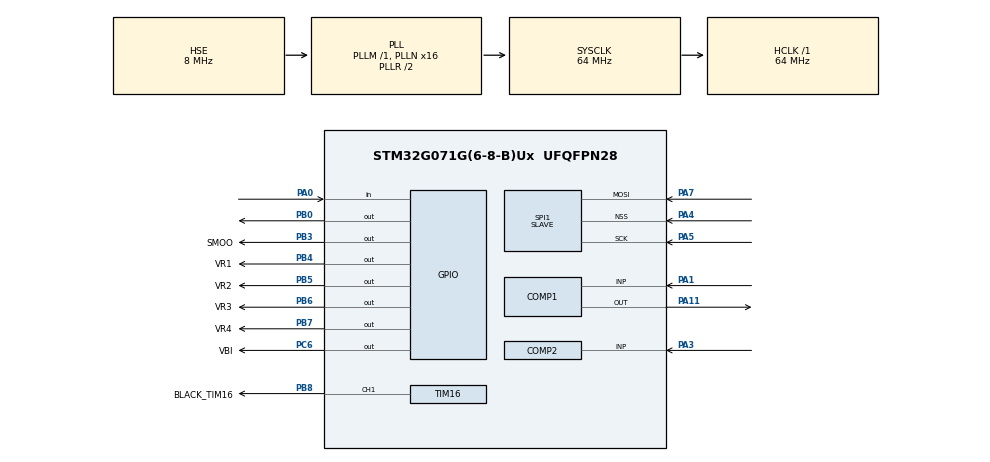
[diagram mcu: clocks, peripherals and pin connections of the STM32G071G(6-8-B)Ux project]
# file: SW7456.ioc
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COMP1.Hysteresis=COMP_HYSTERESIS_LOW
COMP1.Mode=COMP_POWERMODE_MEDIUMSPEED
COMP1.TriggerMode=COMP_TRIGGERMODE_IT_RISING
COMP1.WindowOutput=COMP_WINDOWOUTPUT_EACH_COMP
COMP2.Hysteresis=COMP_HYSTERESIS_LOW
COMP2.Mode=COMP_POWERMODE_MEDIUMSPEED
COMP2.OutputPol=COMP_OUTPUTPOL_NONINVERTED
COMP2.TriggerMode=COMP_TRIGGERMODE_IT_RISING
DAC1.DAC_Channel-DAC_OUT2_Int=DAC_CHANNEL_2
Dma.Request0=SPI1_RX
Dma.Request1=TIM16_CH1
Dma.SPI1_RX.0.Direction=DMA_PERIPH_TO_MEMORY
Dma.SPI1_RX.0.EventEnable=DISABLE
Dma.SPI1_RX.0.Instance=DMA1_Channel2
Dma.SPI1_RX.0.MemDataAlignment=DMA_MDATAALIGN_BYTE
Dma.SPI1_RX.0.MemInc=DMA_MINC_ENABLE
Dma.SPI1_RX.0.Mode=DMA_CIRCULAR
Dma.SPI1_RX.0.PeriphDataAlignment=DMA_PDATAALIGN_BYTE
Dma.SPI1_RX.0.PeriphInc=DMA_PINC_DISABLE
Dma.SPI1_RX.0.Polarity=HAL_DMAMUX_REQ_GEN_RISING
Dma.SPI1_RX.0.Priority=DMA_PRIORITY_LOW
Dma.SPI1_RX.0.RequestNumber=1
Dma.SPI1_RX.0.SignalID=NONE
Dma.SPI1_RX.0.SyncEnable=DISABLE
Dma.SPI1_RX.0.SyncPolarity=HAL_DMAMUX_SYNC_NO_EVENT
Dma.SPI1_RX.0.SyncRequestNumber=1
Dma.SPI1_RX.0.SyncSignalID=NONE
Dma.TIM16_CH1.1.Direction=DMA_MEMORY_TO_PERIPH
Dma.TIM16_CH1.1.EventEnable=DISABLE
Dma.TIM16_CH1.1.Instance=DMA1_Channel5
Dma.TIM16_CH1.1.MemDataAlignment=DMA_MDATAALIGN_HALFWORD
Dma.TIM16_CH1.1.MemInc=DMA_MINC_ENABLE
Dma.TIM16_CH1.1.Mode=DMA_CIRCULAR
Dma.TIM16_CH1.1.PeriphDataAlignment=DMA_PDATAALIGN_HALFWORD
Dma.TIM16_CH1.1.PeriphInc=DMA_PINC_DISABLE
Dma.TIM16_CH1.1.Polarity=HAL_DMAMUX_REQ_GEN_RISING
Dma.TIM16_CH1.1.Priority=DMA_PRIORITY_VERY_HIGH
Dma.TIM16_CH1.1.RequestNumber=1
Dma.TIM16_CH1.1.SignalID=NONE
Dma.TIM16_CH1.1.SyncEnable=DISABLE
Dma.TIM16_CH1.1.SyncPolarity=HAL_DMAMUX_SYNC_NO_EVENT
Dma.TIM16_CH1.1.SyncRequestNumber=1
Dma.TIM16_CH1.1.SyncSignalID=NONE
LPTIM1.TriggerSource=LPTIM_TRIGSOURCE_6
Mcu.Family=STM32G0
Mcu.Name=STM32G071G(6-8-B)Ux
Mcu.Package=UFQFPN28
NVIC.ADC1_COMP_IRQn=true\:0\:0\:true\:false\:true\:false\:true\:true
NVIC.DMA1_Ch4_7_DMAMUX1_OVR_IRQn=true\:0\:0\:false\:false\:true\:false\:true\:true
NVIC.DMA1_Channel2_3_IRQn=true\:3\:0\:true\:false\:true\:false\:true\:true
PA0.GPIO_PuPd=GPIO_PULLDOWN
PA0.Signal=GPIO_Input
PA1.Mode=INP
PA1.Signal=COMP1_INP
PA11\ [PA9].Mode=ExternalOutput
PA11\ [PA9].Signal=COMP1_OUT
PA12\ [PA10].GPIO_Speed=GPIO_SPEED_FREQ_MEDIUM
PA12\ [PA10].PinState=GPIO_PIN_SET
PA12\ [PA10].Signal=COMP2_OUT
PA13.Mode=Serial_Wire
PA13.Signal=SYS_SWDIO
PA14-BOOT0.Mode=Serial_Wire
PA14-BOOT0.Signal=SYS_SWCLK
PA3.Mode=INP
PA3.Signal=COMP2_INP
PA4.GPIO_PuPd=GPIO_PULLUP
PA4.GPIO_Speed=GPIO_SPEED_FREQ_HIGH
PA4.Mode=NSS_Signal_Hard_Input
PA4.Signal=SPI1_NSS
PA5.GPIO_PuPd=GPIO_PULLUP
PA5.GPIO_Speed=GPIO_SPEED_FREQ_HIGH
PA5.Mode=RX_Only_Simplex_Unidirect_Slave
PA5.Signal=SPI1_SCK
PA6.Signal=SPI1_MISO
PA7.GPIO_PuPd=GPIO_PULLUP
PA7.GPIO_Speed=GPIO_SPEED_FREQ_HIGH
PA7.Mode=RX_Only_Simplex_Unidirect_Slave
PA7.Signal=SPI1_MOSI
PB0.GPIO_ModeDefaultOutputPP=GPIO_MODE_OUTPUT_PP
PB0.GPIO_Speed=GPIO_SPEED_FREQ_VERY_HIGH
PB0.Signal=GPIO_Output
PB3.GPIO_Label=SMOO
PB3.GPIO_ModeDefaultOutputPP=GPIO_MODE_OUTPUT_OD
PB3.GPIO_Speed=GPIO_SPEED_FREQ_HIGH
PB3.PinState=GPIO_PIN_SET
PB3.Signal=GPIO_Output
PB4.GPIO_Label=VR1
PB4.GPIO_Speed=GPIO_SPEED_FREQ_MEDIUM
PB4.Signal=GPIO_Output
PB5.GPIO_Label=VR2
PB5.GPIO_Speed=GPIO_SPEED_FREQ_MEDIUM
PB5.Signal=GPIO_Output
PB6.GPIO_Label=VR3
PB6.GPIO_PuPd=GPIO_NOPULL
PB6.GPIO_Speed=GPIO_SPEED_FREQ_MEDIUM
PB6.Signal=GPIO_Output
PB7.GPIO_Label=VR4
PB7.GPIO_Speed=GPIO_SPEED_FREQ_MEDIUM
PB7.Signal=GPIO_Output
PB8.GPIO_Label=BLACK_TIM16
PB8.Signal=S_TIM16_CH1
PC14-OSC32_IN\ (PC14).Mode=HSE-External-Clock-Source
PC14-OSC32_IN\ (PC14).Signal=RCC_OSC_IN
PC6.GPIO_Label=VBI
PC6.Signal=GPIO_Output
ProjectManager.HeapSize=0x0
ProjectManager.StackSize=0x100
ProjectManager.TargetToolchain=STM32CubeIDE
RCC.ADCFreq_Value=64000000
RCC.AHBFreq_Value=64000000
RCC.CortexFreq_Value=64000000
RCC.EXTERNAL_CLOCK_VALUE=48000
RCC.HCLKFreq_Value=64000000
RCC.HSE_VALUE=8000000
RCC.HSI_VALUE=16000000
RCC.LSE_VALUE=32768
RCC.PLLN=16
RCC.PLLQ=RCC_PLLQ_DIV8
RCC.PLLSourceVirtual=RCC_PLLSOURCE_HSE
RCC.SYSCLKFreq_VALUE=64000000
RCC.SYSCLKSource=RCC_SYSCLKSOURCE_PLLCLK
RCC.VCOOutputFreq_Value=128000000
SH.S_TIM16_CH1.0=TIM16_CH1,PWM Generation1 CH1
SPI1.CLKPhase=SPI_PHASE_2EDGE
SPI1.CLKPolarity=SPI_POLARITY_HIGH
SPI1.DataSize=SPI_DATASIZE_8BIT
SPI1.Direction=SPI_DIRECTION_2LINES_RXONLY
SPI1.FirstBit=SPI_FIRSTBIT_MSB
SPI1.Mode=SPI_MODE_SLAVE
SPI1.VirtualNSS=VM_NSSHARD
SPI1.VirtualType=VM_SLAVE
TIM1.AutoReloadPreload=TIM_AUTORELOAD_PRELOAD_ENABLE
TIM1.Period=40000
TIM1.Prescaler=31
TIM1.RepetitionCounter=0
TIM14.AutoReloadPreload=TIM_AUTORELOAD_PRELOAD_ENABLE
TIM14.Channel=TIM_CHANNEL_1
TIM14.ClockDivision=TIM_CLOCKDIVISION_DIV1
TIM14.ICFilter_CH1=2
TIM14.ICPrescaler=TIM_ICPSC_DIV1
TIM14.Period=65535
TIM14.TIM14_TI1_REMAP=TIM_TIM14_TI1_HSE_32
TIM16.Channel=TIM_CHANNEL_1
TIM16.OC1Preload_PWM=ENABLE
TIM16.OCFastMode_PWM=TIM_OCFAST_DISABLE
TIM16.OCIdleState_1=TIM_OCIDLESTATE_RESET
TIM16.OCMode_PWM=TIM_OCMODE_PWM2
TIM16.Period=2034
TIM16.Pulse=0
TIM2.AutoReloadPreload=TIM_AUTORELOAD_PRELOAD_ENABLE
TIM2.Channel-Input_Capture2_from_TI2_Remap_TIM2=TIM_CHANNEL_2
TIM2.ICFilter_CH2=0
TIM2.ICPolarity_CH2=TIM_INPUTCHANNELPOLARITY_RISING
TIM2.ICPrescaler-Input_Capture2_from_TI2_Remap_TIM2=TIM_ICPSC_DIV1
TIM2.Period=32000
TIM2.Slave_TriggerPrescaler=TIM_TRIGGERPRESCALER_DIV1
TIM2.TIM2_ETR_REMAP-TriggerSource_ETR_Remap_TIM2=TIM_TIM2_ETR_COMP2
TIM2.TIM_MasterOutputTrigger=TIM_TRGO_OC1REF
TIM2.TIM_MasterSlaveMode=TIM_MASTERSLAVEMODE_DISABLE
TIM3.AutoReloadPreload=TIM_AUTORELOAD_PRELOAD_ENABLE
TIM3.Channel-Input_Capture1_from_TI1_REMAP_TIM3=TIM_CHANNEL_1
TIM3.Period=65535
TIM3.Slave_TriggerPolarity=TIM_TRIGGERPOLARITY_NONINVERTED
TIM3.Slave_TriggerPrescaler=TIM_TRIGGERPRESCALER_DIV1
TIM3.TIM3_ETR_REMAP-TriggerSource_ETR_Remap_TIM3=TIM_TIM3_ETR_COMP1
TIM3.TIM_MasterOutputTrigger=TIM_TRGO_OC1REF
TIM6.AutoReloadPreload=TIM_AUTORELOAD_PRELOAD_ENABLE
TIM6.Period=0xffff
TIM6.TIM_MasterOutputTrigger=TIM_TRGO_ENABLE
VP_COMP1_VS_DACOUT2.Mode=INM_DACOUT2
VP_COMP2_VS_DACOUT2.Mode=INM_DACOUT2
VP_DAC1_VS_DACI2.Mode=DAC_OUT2_Int
VP_LPTIM1_VS_LPTIM_counterModeInternalClock.Mode=Counts__internal_clock_event_00
VP_SYS_VS_DBSignals.Mode=DisableDeadBatterySignals
VP_TIM14_VS_ClockSourceINT.Mode=Enable_Timer
VP_TIM14_VS_NoInput1.Mode=Input_Capture1_from_TI1_REMAP_TIM14
VP_TIM16_VS_ClockSourceINT.Mode=Enable_Timer
VP_TIM1_VS_ClockSourceINT.Mode=Internal
VP_TIM2_VS_ClockSourceINT.Mode=Internal
VP_TIM2_VS_ControllerModeCombinedResetTrigger.Mode=Combined_Reset_Trigger_Mode
VP_TIM2_VS_NoETR.Mode=TriggerSource_ETR_Remap_TIM2
VP_TIM2_VS_NoInput2.Mode=Input_Capture2_from_TI2_Remap_TIM2
VP_TIM3_VS_ClockSourceINT.Mode=Internal
VP_TIM3_VS_ControllerModeCombinedResetTrigger.Mode=Combined_Reset_Trigger_Mode
VP_TIM3_VS_NoETR.Mode=TriggerSource_ETR_Remap_TIM3
VP_TIM3_VS_NoInput1.Mode=Input_Capture1_from_TI1_REMAP_TIM3
VP_TIM6_VS_ClockSourceINT.Mode=Enable_Timer
board=custom

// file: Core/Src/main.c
/* USER CODE BEGIN Header */
/**
  ******************************************************************************
  * @file           : main.c
  * @brief          : Main program body
  ******************************************************************************
  * @attention
  *
  * Copyright (c) 2024 STMicroelectronics.
  * All rights reserved.
  *
  * This software is licensed under terms that can be found in the LICENSE file
  * in the root directory of this software component.
  * If no LICENSE file comes with this software, it is provided AS-IS.
  *
  ******************************************************************************
  */
/* USER CODE END Header */
#include "main.h"

/* USER CODE BEGIN Includes */
#include "osd_glue.h"
/* USER CODE END Includes */

COMP_HandleTypeDef hcomp1;
COMP_HandleTypeDef hcomp2;

DAC_HandleTypeDef hdac1;

LPTIM_HandleTypeDef hlptim1;

SPI_HandleTypeDef hspi1;
DMA_HandleTypeDef hdma_spi1_rx;

TIM_HandleTypeDef htim1;
TIM_HandleTypeDef htim2;
TIM_HandleTypeDef htim3;
TIM_HandleTypeDef htim6;
TIM_HandleTypeDef htim14;
TIM_HandleTypeDef htim16;
DMA_HandleTypeDef hdma_tim16_ch1;

void SystemClock_Config(void);
static void MX_GPIO_Init(void);
static void MX_DMA_Init(void);
static void MX_COMP1_Init(void);
static void MX_DAC1_Init(void);
static void MX_TIM3_Init(void);
static void MX_TIM6_Init(void);
static void MX_TIM2_Init(void);
static void MX_LPTIM1_Init(void);
static void MX_SPI1_Init(void);
static void MX_COMP2_Init(void);
static void MX_TIM1_Init(void);
static void MX_TIM14_Init(void);
static void MX_TIM16_Init(void);

int main(void)
{

  /* MCU Configuration--------------------------------------------------------*/

  /* Reset of all peripherals, Initializes the Flash interface and the Systick. */
  HAL_Init();

  /* Configure the system clock */
  SystemClock_Config();

  /* Initialize all configured peripherals */
  MX_GPIO_Init();
  MX_DMA_Init();
  MX_COMP1_Init();
  MX_DAC1_Init();
  MX_TIM3_Init();
  MX_TIM6_Init();
  MX_TIM2_Init();
  MX_LPTIM1_Init();
  MX_SPI1_Init();
  MX_COMP2_Init();
  MX_TIM1_Init();
  MX_TIM14_Init();
  MX_TIM16_Init();
  /* USER CODE BEGIN 2 */
  osd_init();
  osd_loop();
  /* USER CODE END 2 */

  /* Infinite loop */
  while (1)
  {

  }
}

void SystemClock_Config(void)
{
  RCC_OscInitTypeDef RCC_OscInitStruct = {0};
  RCC_ClkInitTypeDef RCC_ClkInitStruct = {0};

  /** Configure the main internal regulator output voltage
  */
  HAL_PWREx_ControlVoltageScaling(PWR_REGULATOR_VOLTAGE_SCALE1);

  /** Initializes the RCC Oscillators according to the specified parameters
  * in the RCC_OscInitTypeDef structure.
  */
  RCC_OscInitStruct.OscillatorType = RCC_OSCILLATORTYPE_HSE;
  RCC_OscInitStruct.HSEState = RCC_HSE_BYPASS;
  RCC_OscInitStruct.PLL.PLLState = RCC_PLL_ON;
  RCC_OscInitStruct.PLL.PLLSource = RCC_PLLSOURCE_HSE;
  RCC_OscInitStruct.PLL.PLLM = RCC_PLLM_DIV1;
  RCC_OscInitStruct.PLL.PLLN = 16;
  RCC_OscInitStruct.PLL.PLLP = RCC_PLLP_DIV2;
  RCC_OscInitStruct.PLL.PLLQ = RCC_PLLQ_DIV8;
  RCC_OscInitStruct.PLL.PLLR = RCC_PLLR_DIV2;
  if (HAL_RCC_OscConfig(&RCC_OscInitStruct) != HAL_OK)
  {
    Error_Handler();
  }

  /** Initializes the CPU, AHB and APB buses clocks
  */
  RCC_ClkInitStruct.ClockType = RCC_CLOCKTYPE_HCLK|RCC_CLOCKTYPE_SYSCLK
                              |RCC_CLOCKTYPE_PCLK1;
  RCC_ClkInitStruct.SYSCLKSource = RCC_SYSCLKSOURCE_PLLCLK;
  RCC_ClkInitStruct.AHBCLKDivider = RCC_SYSCLK_DIV1;
  RCC_ClkInitStruct.APB1CLKDivider = RCC_HCLK_DIV1;

  if (HAL_RCC_ClockConfig(&RCC_ClkInitStruct, FLASH_LATENCY_2) != HAL_OK)
  {
    Error_Handler();
  }
}

static void MX_COMP1_Init(void)
{

  hcomp1.Instance = COMP1;
  hcomp1.Init.InputPlus = COMP_INPUT_PLUS_IO3;
  hcomp1.Init.InputMinus = COMP_INPUT_MINUS_DAC1_CH2;
  hcomp1.Init.OutputPol = COMP_OUTPUTPOL_NONINVERTED;
  hcomp1.Init.WindowOutput = COMP_WINDOWOUTPUT_EACH_COMP;
  hcomp1.Init.Hysteresis = COMP_HYSTERESIS_LOW;
  hcomp1.Init.BlankingSrce = COMP_BLANKINGSRC_NONE;
  hcomp1.Init.Mode = COMP_POWERMODE_MEDIUMSPEED;
  hcomp1.Init.WindowMode = COMP_WINDOWMODE_DISABLE;
  hcomp1.Init.TriggerMode = COMP_TRIGGERMODE_IT_RISING;
  if (HAL_COMP_Init(&hcomp1) != HAL_OK)
  {
    Error_Handler();
  }

}

static void MX_COMP2_Init(void)
{

  hcomp2.Instance = COMP2;
  hcomp2.Init.InputPlus = COMP_INPUT_PLUS_IO3;
  hcomp2.Init.InputMinus = COMP_INPUT_MINUS_DAC1_CH2;
  hcomp2.Init.OutputPol = COMP_OUTPUTPOL_NONINVERTED;
  hcomp2.Init.WindowOutput = COMP_WINDOWOUTPUT_EACH_COMP;
  hcomp2.Init.Hysteresis = COMP_HYSTERESIS_LOW;
  hcomp2.Init.BlankingSrce = COMP_BLANKINGSRC_NONE;
  hcomp2.Init.Mode = COMP_POWERMODE_MEDIUMSPEED;
  hcomp2.Init.WindowMode = COMP_WINDOWMODE_DISABLE;
  hcomp2.Init.TriggerMode = COMP_TRIGGERMODE_IT_RISING;
  if (HAL_COMP_Init(&hcomp2) != HAL_OK)
  {
    Error_Handler();
  }

}

static void MX_DAC1_Init(void)
{

  DAC_ChannelConfTypeDef sConfig = {0};

  /** DAC Initialization
  */
  hdac1.Instance = DAC1;
  if (HAL_DAC_Init(&hdac1) != HAL_OK)
  {
    Error_Handler();
  }

  /** DAC channel OUT2 config
  */
  sConfig.DAC_SampleAndHold = DAC_SAMPLEANDHOLD_DISABLE;
  sConfig.DAC_Trigger = DAC_TRIGGER_NONE;
  sConfig.DAC_OutputBuffer = DAC_OUTPUTBUFFER_DISABLE;
  sConfig.DAC_ConnectOnChipPeripheral = DAC_CHIPCONNECT_ENABLE;
  sConfig.DAC_UserTrimming = DAC_TRIMMING_FACTORY;
  if (HAL_DAC_ConfigChannel(&hdac1, &sConfig, DAC_CHANNEL_2) != HAL_OK)
  {
    Error_Handler();
  }

}

static void MX_LPTIM1_Init(void)
{

  hlptim1.Instance = LPTIM1;
  hlptim1.Init.Clock.Source = LPTIM_CLOCKSOURCE_APBCLOCK_LPOSC;
  hlptim1.Init.Clock.Prescaler = LPTIM_PRESCALER_DIV1;
  hlptim1.Init.Trigger.Source = LPTIM_TRIGSOURCE_6;
  hlptim1.Init.Trigger.ActiveEdge = LPTIM_ACTIVEEDGE_RISING;
  hlptim1.Init.Trigger.SampleTime = LPTIM_TRIGSAMPLETIME_DIRECTTRANSITION;
  hlptim1.Init.OutputPolarity = LPTIM_OUTPUTPOLARITY_HIGH;
  hlptim1.Init.UpdateMode = LPTIM_UPDATE_IMMEDIATE;
  hlptim1.Init.CounterSource = LPTIM_COUNTERSOURCE_INTERNAL;
  hlptim1.Init.Input1Source = LPTIM_INPUT1SOURCE_GPIO;
  hlptim1.Init.Input2Source = LPTIM_INPUT2SOURCE_GPIO;
  if (HAL_LPTIM_Init(&hlptim1) != HAL_OK)
  {
    Error_Handler();
  }

}

static void MX_SPI1_Init(void)
{

  /* SPI1 parameter configuration*/
  hspi1.Instance = SPI1;
  hspi1.Init.Mode = SPI_MODE_SLAVE;
  hspi1.Init.Direction = SPI_DIRECTION_2LINES_RXONLY;
  hspi1.Init.DataSize = SPI_DATASIZE_8BIT;
  hspi1.Init.CLKPolarity = SPI_POLARITY_HIGH;
  hspi1.Init.CLKPhase = SPI_PHASE_2EDGE;
  hspi1.Init.NSS = SPI_NSS_HARD_INPUT;
  hspi1.Init.FirstBit = SPI_FIRSTBIT_MSB;
  hspi1.Init.TIMode = SPI_TIMODE_DISABLE;
  hspi1.Init.CRCCalculation = SPI_CRCCALCULATION_DISABLE;
  hspi1.Init.CRCPolynomial = 7;
  hspi1.Init.CRCLength = SPI_CRC_LENGTH_DATASIZE;
  hspi1.Init.NSSPMode = SPI_NSS_PULSE_DISABLE;
  if (HAL_SPI_Init(&hspi1) != HAL_OK)
  {
    Error_Handler();
  }

}

static void MX_TIM1_Init(void)
{

  TIM_ClockConfigTypeDef sClockSourceConfig = {0};
  TIM_MasterConfigTypeDef sMasterConfig = {0};

  htim1.Instance = TIM1;
  htim1.Init.Prescaler = 31;
  htim1.Init.CounterMode = TIM_COUNTERMODE_UP;
  htim1.Init.Period = 40000;
  htim1.Init.ClockDivision = TIM_CLOCKDIVISION_DIV1;
  htim1.Init.RepetitionCounter = 0;
  htim1.Init.AutoReloadPreload = TIM_AUTORELOAD_PRELOAD_ENABLE;
  if (HAL_TIM_Base_Init(&htim1) != HAL_OK)
  {
    Error_Handler();
  }
  sClockSourceConfig.ClockSource = TIM_CLOCKSOURCE_INTERNAL;
  if (HAL_TIM_ConfigClockSource(&htim1, &sClockSourceConfig) != HAL_OK)
  {
    Error_Handler();
  }
  sMasterConfig.MasterOutputTrigger = TIM_TRGO_RESET;
  sMasterConfig.MasterOutputTrigger2 = TIM_TRGO2_RESET;
  sMasterConfig.MasterSlaveMode = TIM_MASTERSLAVEMODE_DISABLE;
  if (HAL_TIMEx_MasterConfigSynchronization(&htim1, &sMasterConfig) != HAL_OK)
  {
    Error_Handler();
  }

}

static void MX_TIM2_Init(void)
{

  TIM_ClockConfigTypeDef sClockSourceConfig = {0};
  TIM_SlaveConfigTypeDef sSlaveConfig = {0};
  TIM_MasterConfigTypeDef sMasterConfig = {0};
  TIM_IC_InitTypeDef sConfigIC = {0};

  htim2.Instance = TIM2;
  htim2.Init.Prescaler = 0;
  htim2.Init.CounterMode = TIM_COUNTERMODE_UP;
  htim2.Init.Period = 32000;
  htim2.Init.ClockDivision = TIM_CLOCKDIVISION_DIV1;
  htim2.Init.AutoReloadPreload = TIM_AUTORELOAD_PRELOAD_ENABLE;
  if (HAL_TIM_Base_Init(&htim2) != HAL_OK)
  {
    Error_Handler();
  }
  sClockSourceConfig.ClockSource = TIM_CLOCKSOURCE_INTERNAL;
  if (HAL_TIM_ConfigClockSource(&htim2, &sClockSourceConfig) != HAL_OK)
  {
    Error_Handler();
  }
  if (HAL_TIM_IC_Init(&htim2) != HAL_OK)
  {
    Error_Handler();
  }
  sSlaveConfig.SlaveMode = TIM_SLAVEMODE_COMBINED_RESETTRIGGER;
  sSlaveConfig.InputTrigger = TIM_TS_ETRF;
  sSlaveConfig.TriggerPolarity = TIM_TRIGGERPOLARITY_NONINVERTED;
  sSlaveConfig.TriggerPrescaler = TIM_TRIGGERPRESCALER_DIV1;
  sSlaveConfig.TriggerFilter = 0;
  if (HAL_TIM_SlaveConfigSynchro(&htim2, &sSlaveConfig) != HAL_OK)
  {
    Error_Handler();
  }
  sMasterConfig.MasterOutputTrigger = TIM_TRGO_OC1REF;
  sMasterConfig.MasterSlaveMode = TIM_MASTERSLAVEMODE_DISABLE;
  if (HAL_TIMEx_MasterConfigSynchronization(&htim2, &sMasterConfig) != HAL_OK)
  {
    Error_Handler();
  }
  if (HAL_TIMEx_RemapConfig(&htim2, TIM_TIM2_ETR_COMP2) != HAL_OK)
  {
    Error_Handler();
  }
  sConfigIC.ICPolarity = TIM_INPUTCHANNELPOLARITY_RISING;
  sConfigIC.ICSelection = TIM_ICSELECTION_DIRECTTI;
  sConfigIC.ICPrescaler = TIM_ICPSC_DIV1;
  sConfigIC.ICFilter = 0;
  if (HAL_TIM_IC_ConfigChannel(&htim2, &sConfigIC, TIM_CHANNEL_2) != HAL_OK)
  {
    Error_Handler();
  }
  if (HAL_TIMEx_TISelection(&htim2, TIM_TIM2_TI2_COMP2, TIM_CHANNEL_2) != HAL_OK)
  {
    Error_Handler();
  }

}

static void MX_TIM3_Init(void)
{

  TIM_ClockConfigTypeDef sClockSourceConfig = {0};
  TIM_SlaveConfigTypeDef sSlaveConfig = {0};
  TIM_MasterConfigTypeDef sMasterConfig = {0};
  TIM_IC_InitTypeDef sConfigIC = {0};

  htim3.Instance = TIM3;
  htim3.Init.Prescaler = 0;
  htim3.Init.CounterMode = TIM_COUNTERMODE_UP;
  htim3.Init.Period = 65535;
  htim3.Init.ClockDivision = TIM_CLOCKDIVISION_DIV1;
  htim3.Init.AutoReloadPreload = TIM_AUTORELOAD_PRELOAD_ENABLE;
  if (HAL_TIM_Base_Init(&htim3) != HAL_OK)
  {
    Error_Handler();
  }
  sClockSourceConfig.ClockSource = TIM_CLOCKSOURCE_INTERNAL;
  if (HAL_TIM_ConfigClockSource(&htim3, &sClockSourceConfig) != HAL_OK)
  {
    Error_Handler();
  }
  if (HAL_TIM_IC_Init(&htim3) != HAL_OK)
  {
    Error_Handler();
  }
  sSlaveConfig.SlaveMode = TIM_SLAVEMODE_COMBINED_RESETTRIGGER;
  sSlaveConfig.InputTrigger = TIM_TS_ETRF;
  sSlaveConfig.TriggerPolarity = TIM_TRIGGERPOLARITY_NONINVERTED;
  sSlaveConfig.TriggerPrescaler = TIM_TRIGGERPRESCALER_DIV1;
  sSlaveConfig.TriggerFilter = 0;
  if (HAL_TIM_SlaveConfigSynchro(&htim3, &sSlaveConfig) != HAL_OK)
  {
    Error_Handler();
  }
  sMasterConfig.MasterOutputTrigger = TIM_TRGO_OC1REF;
  sMasterConfig.MasterSlaveMode = TIM_MASTERSLAVEMODE_DISABLE;
  if (HAL_TIMEx_MasterConfigSynchronization(&htim3, &sMasterConfig) != HAL_OK)
  {
    Error_Handler();
  }
  if (HAL_TIMEx_RemapConfig(&htim3, TIM_TIM3_ETR_COMP1) != HAL_OK)
  {
    Error_Handler();
  }
  sConfigIC.ICPolarity = TIM_INPUTCHANNELPOLARITY_RISING;
  sConfigIC.ICSelection = TIM_ICSELECTION_DIRECTTI;
  sConfigIC.ICPrescaler = TIM_ICPSC_DIV1;
  sConfigIC.ICFilter = 0;
  if (HAL_TIM_IC_ConfigChannel(&htim3, &sConfigIC, TIM_CHANNEL_1) != HAL_OK)
  {
    Error_Handler();
  }
  if (HAL_TIMEx_TISelection(&htim3, TIM_TIM3_TI1_COMP1, TIM_CHANNEL_1) != HAL_OK)
  {
    Error_Handler();
  }

}

static void MX_TIM6_Init(void)
{

  TIM_MasterConfigTypeDef sMasterConfig = {0};

  htim6.Instance = TIM6;
  htim6.Init.Prescaler = 0;
  htim6.Init.CounterMode = TIM_COUNTERMODE_UP;
  htim6.Init.Period = 0xffff;
  htim6.Init.AutoReloadPreload = TIM_AUTORELOAD_PRELOAD_ENABLE;
  if (HAL_TIM_Base_Init(&htim6) != HAL_OK)
  {
    Error_Handler();
  }
  sMasterConfig.MasterOutputTrigger = TIM_TRGO_ENABLE;
  sMasterConfig.MasterSlaveMode = TIM_MASTERSLAVEMODE_DISABLE;
  if (HAL_TIMEx_MasterConfigSynchronization(&htim6, &sMasterConfig) != HAL_OK)
  {
    Error_Handler();
  }

}

static void MX_TIM14_Init(void)
{

  TIM_IC_InitTypeDef sConfigIC = {0};

  htim14.Instance = TIM14;
  htim14.Init.Prescaler = 0;
  htim14.Init.CounterMode = TIM_COUNTERMODE_UP;
  htim14.Init.Period = 65535;
  htim14.Init.ClockDivision = TIM_CLOCKDIVISION_DIV1;
  htim14.Init.AutoReloadPreload = TIM_AUTORELOAD_PRELOAD_ENABLE;
  if (HAL_TIM_Base_Init(&htim14) != HAL_OK)
  {
    Error_Handler();
  }
  if (HAL_TIM_IC_Init(&htim14) != HAL_OK)
  {
    Error_Handler();
  }
  sConfigIC.ICPolarity = TIM_INPUTCHANNELPOLARITY_RISING;
  sConfigIC.ICSelection = TIM_ICSELECTION_DIRECTTI;
  sConfigIC.ICPrescaler = TIM_ICPSC_DIV1;
  sConfigIC.ICFilter = 2;
  if (HAL_TIM_IC_ConfigChannel(&htim14, &sConfigIC, TIM_CHANNEL_1) != HAL_OK)
  {
    Error_Handler();
  }
  if (HAL_TIMEx_TISelection(&htim14, TIM_TIM14_TI1_HSE_32, TIM_CHANNEL_1) != HAL_OK)
  {
    Error_Handler();
  }

}

static void MX_TIM16_Init(void)
{

  TIM_OC_InitTypeDef sConfigOC = {0};
  TIM_BreakDeadTimeConfigTypeDef sBreakDeadTimeConfig = {0};

  htim16.Instance = TIM16;
  htim16.Init.Prescaler = 0;
  htim16.Init.CounterMode = TIM_COUNTERMODE_UP;
  htim16.Init.Period = 2034;
  htim16.Init.ClockDivision = TIM_CLOCKDIVISION_DIV1;
  htim16.Init.RepetitionCounter = 0;
  htim16.Init.AutoReloadPreload = TIM_AUTORELOAD_PRELOAD_DISABLE;
  if (HAL_TIM_Base_Init(&htim16) != HAL_OK)
  {
    Error_Handler();
  }
  if (HAL_TIM_PWM_Init(&htim16) != HAL_OK)
  {
    Error_Handler();
  }
  sConfigOC.OCMode = TIM_OCMODE_PWM2;
  sConfigOC.Pulse = 0;
  sConfigOC.OCPolarity = TIM_OCPOLARITY_HIGH;
  sConfigOC.OCNPolarity = TIM_OCNPOLARITY_HIGH;
  sConfigOC.OCFastMode = TIM_OCFAST_DISABLE;
  sConfigOC.OCIdleState = TIM_OCIDLESTATE_RESET;
  sConfigOC.OCNIdleState = TIM_OCNIDLESTATE_RESET;
  if (HAL_TIM_PWM_ConfigChannel(&htim16, &sConfigOC, TIM_CHANNEL_1) != HAL_OK)
  {
    Error_Handler();
  }
  sBreakDeadTimeConfig.OffStateRunMode = TIM_OSSR_DISABLE;
  sBreakDeadTimeConfig.OffStateIDLEMode = TIM_OSSI_DISABLE;
  sBreakDeadTimeConfig.LockLevel = TIM_LOCKLEVEL_OFF;
  sBreakDeadTimeConfig.DeadTime = 0;
  sBreakDeadTimeConfig.BreakState = TIM_BREAK_DISABLE;
  sBreakDeadTimeConfig.BreakPolarity = TIM_BREAKPOLARITY_HIGH;
  sBreakDeadTimeConfig.BreakFilter = 0;
  sBreakDeadTimeConfig.AutomaticOutput = TIM_AUTOMATICOUTPUT_DISABLE;
  if (HAL_TIMEx_ConfigBreakDeadTime(&htim16, &sBreakDeadTimeConfig) != HAL_OK)
  {
    Error_Handler();
  }
  HAL_TIM_MspPostInit(&htim16);

}

static void MX_DMA_Init(void)
{

  /* DMA controller clock enable */
  __HAL_RCC_DMA1_CLK_ENABLE();

  /* DMA interrupt init */
  /* DMA1_Channel2_3_IRQn interrupt configuration */
  HAL_NVIC_SetPriority(DMA1_Channel2_3_IRQn, 3, 0);
  HAL_NVIC_EnableIRQ(DMA1_Channel2_3_IRQn);
  /* DMA1_Ch4_7_DMAMUX1_OVR_IRQn interrupt configuration */
  HAL_NVIC_SetPriority(DMA1_Ch4_7_DMAMUX1_OVR_IRQn, 0, 0);
  HAL_NVIC_EnableIRQ(DMA1_Ch4_7_DMAMUX1_OVR_IRQn);

}

static void MX_GPIO_Init(void)
{
  GPIO_InitTypeDef GPIO_InitStruct = {0};

  /* GPIO Ports Clock Enable */
  __HAL_RCC_GPIOC_CLK_ENABLE();
  __HAL_RCC_GPIOA_CLK_ENABLE();
  __HAL_RCC_GPIOB_CLK_ENABLE();

  /*Configure GPIO pin Output Level */
  HAL_GPIO_WritePin(GPIOB, GPIO_PIN_0|VR1_Pin|VR2_Pin|VR3_Pin
                          |VR4_Pin, GPIO_PIN_RESET);

  /*Configure GPIO pin Output Level */
  HAL_GPIO_WritePin(VBI_GPIO_Port, VBI_Pin, GPIO_PIN_RESET);

  /*Configure GPIO pin Output Level */
  HAL_GPIO_WritePin(SMOO_GPIO_Port, SMOO_Pin, GPIO_PIN_SET);

  /*Configure GPIO pin : PA0 */
  GPIO_InitStruct.Pin = GPIO_PIN_0;
  GPIO_InitStruct.Mode = GPIO_MODE_INPUT;
  GPIO_InitStruct.Pull = GPIO_PULLDOWN;
  HAL_GPIO_Init(GPIOA, &GPIO_InitStruct);

  /*Configure GPIO pin : PB0 */
  GPIO_InitStruct.Pin = GPIO_PIN_0;
  GPIO_InitStruct.Mode = GPIO_MODE_OUTPUT_PP;
  GPIO_InitStruct.Pull = GPIO_NOPULL;
  GPIO_InitStruct.Speed = GPIO_SPEED_FREQ_VERY_HIGH;
  HAL_GPIO_Init(GPIOB, &GPIO_InitStruct);

  /*Configure GPIO pin : VBI_Pin */
  GPIO_InitStruct.Pin = VBI_Pin;
  GPIO_InitStruct.Mode = GPIO_MODE_OUTPUT_PP;
  GPIO_InitStruct.Pull = GPIO_NOPULL;
  GPIO_InitStruct.Speed = GPIO_SPEED_FREQ_LOW;
  HAL_GPIO_Init(VBI_GPIO_Port, &GPIO_InitStruct);

  /*Configure GPIO pin : SMOO_Pin */
  GPIO_InitStruct.Pin = SMOO_Pin;
  GPIO_InitStruct.Mode = GPIO_MODE_OUTPUT_OD;
  GPIO_InitStruct.Pull = GPIO_NOPULL;
  GPIO_InitStruct.Speed = GPIO_SPEED_FREQ_HIGH;
  HAL_GPIO_Init(SMOO_GPIO_Port, &GPIO_InitStruct);

  /*Configure GPIO pins : VR1_Pin VR2_Pin VR3_Pin VR4_Pin */
  GPIO_InitStruct.Pin = VR1_Pin|VR2_Pin|VR3_Pin|VR4_Pin;
  GPIO_InitStruct.Mode = GPIO_MODE_OUTPUT_PP;
  GPIO_InitStruct.Pull = GPIO_NOPULL;
  GPIO_InitStruct.Speed = GPIO_SPEED_FREQ_MEDIUM;
  HAL_GPIO_Init(GPIOB, &GPIO_InitStruct);

}

void Error_Handler(void)
{
  __disable_irq();
  while (1)
  {
  }
}
